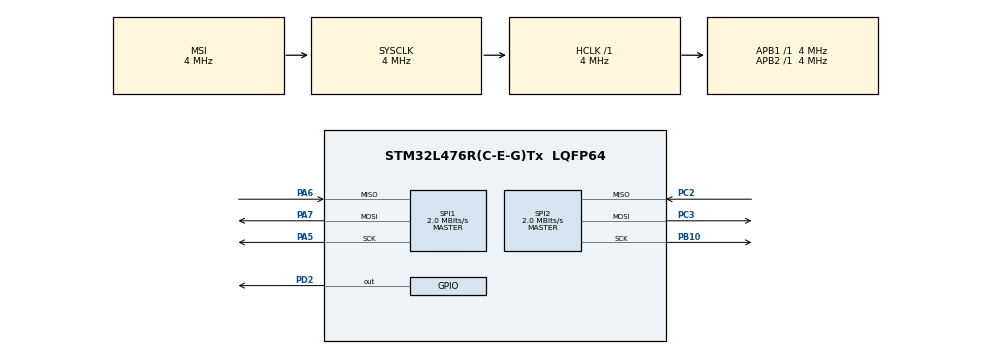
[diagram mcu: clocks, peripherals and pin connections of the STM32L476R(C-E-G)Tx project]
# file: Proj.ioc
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Mcu.Family=STM32L4
Mcu.Name=STM32L476R(C-E-G)Tx
Mcu.Package=LQFP64
NVIC.PriorityGroup=NVIC_PRIORITYGROUP_4
PA5.Mode=Full_Duplex_Master
PA5.Signal=SPI1_SCK
PA6.Mode=Full_Duplex_Master
PA6.Signal=SPI1_MISO
PA7.Mode=Full_Duplex_Master
PA7.Signal=SPI1_MOSI
PB10.Mode=Full_Duplex_Master
PB10.Signal=SPI2_SCK
PC2.Mode=Full_Duplex_Master
PC2.Signal=SPI2_MISO
PC3.Mode=Full_Duplex_Master
PC3.Signal=SPI2_MOSI
PD2.Signal=GPIO_Output
ProjectManager.HeapSize=0x200
ProjectManager.StackSize=0x400
ProjectManager.TargetToolchain=TrueSTUDIO
RCC.ADCFreq_Value=16000000
RCC.AHBFreq_Value=4000000
RCC.APB1Freq_Value=4000000
RCC.APB1TimFreq_Value=4000000
RCC.APB2Freq_Value=4000000
RCC.APB2TimFreq_Value=4000000
RCC.CortexFreq_Value=4000000
RCC.HCLKFreq_Value=4000000
RCC.HSE_VALUE=8000000
RCC.HSI_VALUE=16000000
RCC.LSE_VALUE=32768
RCC.MSI_VALUE=4000000
RCC.PLLN=10
RCC.SYSCLKFreq_VALUE=4000000
RCC.USBFreq_Value=16000000
RCC.VCOOutputFreq_Value=40000000
SPI1.CalculateBaudRate=2.0 MBits/s
SPI1.Direction=SPI_DIRECTION_2LINES
SPI1.Mode=SPI_MODE_MASTER
SPI1.VirtualType=VM_MASTER
SPI2.CalculateBaudRate=2.0 MBits/s
SPI2.Direction=SPI_DIRECTION_2LINES
SPI2.Mode=SPI_MODE_MASTER
SPI2.VirtualType=VM_MASTER
board=custom

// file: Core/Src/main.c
/* USER CODE BEGIN Header */
/**
  ******************************************************************************
  * @file           : main.c
  * @brief          : Main program body
  ******************************************************************************
  * @attention
  *
  * <h2><center>&copy; Copyright (c) 2021 STMicroelectronics.
  * All rights reserved.</center></h2>
  *
  * This software component is licensed by ST under BSD 3-Clause license,
  * the "License"; You may not use this file except in compliance with the
  * License. You may obtain a copy of the License at:
  *                        opensource.org/licenses/BSD-3-Clause
  *
  ******************************************************************************
  */
/* USER CODE END Header */
#include "main.h"

SPI_HandleTypeDef hspi1;
SPI_HandleTypeDef hspi2;

/* USER CODE BEGIN PV */
//некоторые дефайны для управления ножкой Chip Select
#define cs_set() HAL_GPIO_WritePin(GPIOD, GPIO_PIN_2, GPIO_PIN_RESET)
#define cs_reset() HAL_GPIO_WritePin(GPIOD, GPIO_PIN_2, GPIO_PIN_SET)
#define cs_strob() cs_reset();cs_set()
uint8_t aTxBuffer[]={0xFF, 0xFF, 0xFF, 0xFF};

/* USER CODE END PV */

void SystemClock_Config(void);
static void MX_GPIO_Init(void);
static void MX_SPI1_Init(void);
static void MX_SPI2_Init(void);

int main(void)
{
  /* USER CODE BEGIN 1 */
	uint8_t i=0;
  /* USER CODE END 1 */

  /* MCU Configuration--------------------------------------------------------*/

  /* Reset of all peripherals, Initializes the Flash interface and the Systick. */
  HAL_Init();

  /* Configure the system clock */
  SystemClock_Config();

  /* Initialize all configured peripherals */
  MX_GPIO_Init();
  MX_SPI1_Init();
  MX_SPI2_Init();

  /* Infinite loop */
  /* USER CODE BEGIN WHILE */
  while (1)
  {
	  asm("nop");//
		for(i=0;i<=255;i++)
		{
			aTxBuffer[0]=i;
//			aTxBuffer[0]=0xAA;
			HAL_SPI_Transmit (&hspi1, (uint8_t*)aTxBuffer, 1, 0xFFFFFFFF);
			cs_strob();
			HAL_Delay(300);
		}

    /* USER CODE END WHILE */

  }
}

void SystemClock_Config(void)
{
  RCC_OscInitTypeDef RCC_OscInitStruct = {0};
  RCC_ClkInitTypeDef RCC_ClkInitStruct = {0};

  /** Initializes the RCC Oscillators according to the specified parameters
  * in the RCC_OscInitTypeDef structure.
  */
  RCC_OscInitStruct.OscillatorType = RCC_OSCILLATORTYPE_MSI;
  RCC_OscInitStruct.MSIState = RCC_MSI_ON;
  RCC_OscInitStruct.MSICalibrationValue = 0;
  RCC_OscInitStruct.MSIClockRange = RCC_MSIRANGE_6;
  RCC_OscInitStruct.PLL.PLLState = RCC_PLL_NONE;
  if (HAL_RCC_OscConfig(&RCC_OscInitStruct) != HAL_OK)
  {
    Error_Handler();
  }
  /** Initializes the CPU, AHB and APB buses clocks
  */
  RCC_ClkInitStruct.ClockType = RCC_CLOCKTYPE_HCLK|RCC_CLOCKTYPE_SYSCLK
                              |RCC_CLOCKTYPE_PCLK1|RCC_CLOCKTYPE_PCLK2;
  RCC_ClkInitStruct.SYSCLKSource = RCC_SYSCLKSOURCE_MSI;
  RCC_ClkInitStruct.AHBCLKDivider = RCC_SYSCLK_DIV1;
  RCC_ClkInitStruct.APB1CLKDivider = RCC_HCLK_DIV1;
  RCC_ClkInitStruct.APB2CLKDivider = RCC_HCLK_DIV1;

  if (HAL_RCC_ClockConfig(&RCC_ClkInitStruct, FLASH_LATENCY_0) != HAL_OK)
  {
    Error_Handler();
  }
  /** Configure the main internal regulator output voltage
  */
  if (HAL_PWREx_ControlVoltageScaling(PWR_REGULATOR_VOLTAGE_SCALE1) != HAL_OK)
  {
    Error_Handler();
  }
}

static void MX_SPI1_Init(void)
{

  /* SPI1 parameter configuration*/
  hspi1.Instance = SPI1;
  hspi1.Init.Mode = SPI_MODE_MASTER;
  hspi1.Init.Direction = SPI_DIRECTION_2LINES;
  hspi1.Init.DataSize = SPI_DATASIZE_4BIT;
  hspi1.Init.CLKPolarity = SPI_POLARITY_LOW;
  hspi1.Init.CLKPhase = SPI_PHASE_1EDGE;
  hspi1.Init.NSS = SPI_NSS_SOFT;
  hspi1.Init.BaudRatePrescaler = SPI_BAUDRATEPRESCALER_2;
  hspi1.Init.FirstBit = SPI_FIRSTBIT_MSB;
  hspi1.Init.TIMode = SPI_TIMODE_DISABLE;
  hspi1.Init.CRCCalculation = SPI_CRCCALCULATION_DISABLE;
  hspi1.Init.CRCPolynomial = 7;
  hspi1.Init.CRCLength = SPI_CRC_LENGTH_DATASIZE;
  hspi1.Init.NSSPMode = SPI_NSS_PULSE_ENABLE;
  if (HAL_SPI_Init(&hspi1) != HAL_OK)
  {
    Error_Handler();
  }

}

static void MX_SPI2_Init(void)
{

  /* SPI2 parameter configuration*/
  hspi2.Instance = SPI2;
  hspi2.Init.Mode = SPI_MODE_MASTER;
  hspi2.Init.Direction = SPI_DIRECTION_2LINES;
  hspi2.Init.DataSize = SPI_DATASIZE_4BIT;
  hspi2.Init.CLKPolarity = SPI_POLARITY_LOW;
  hspi2.Init.CLKPhase = SPI_PHASE_1EDGE;
  hspi2.Init.NSS = SPI_NSS_SOFT;
  hspi2.Init.BaudRatePrescaler = SPI_BAUDRATEPRESCALER_2;
  hspi2.Init.FirstBit = SPI_FIRSTBIT_MSB;
  hspi2.Init.TIMode = SPI_TIMODE_DISABLE;
  hspi2.Init.CRCCalculation = SPI_CRCCALCULATION_DISABLE;
  hspi2.Init.CRCPolynomial = 7;
  hspi2.Init.CRCLength = SPI_CRC_LENGTH_DATASIZE;
  hspi2.Init.NSSPMode = SPI_NSS_PULSE_ENABLE;
  if (HAL_SPI_Init(&hspi2) != HAL_OK)
  {
    Error_Handler();
  }

}

static void MX_GPIO_Init(void)
{
  GPIO_InitTypeDef GPIO_InitStruct = {0};

  /* GPIO Ports Clock Enable */
  __HAL_RCC_GPIOC_CLK_ENABLE();
  __HAL_RCC_GPIOA_CLK_ENABLE();
  __HAL_RCC_GPIOB_CLK_ENABLE();
  __HAL_RCC_GPIOD_CLK_ENABLE();

  /*Configure GPIO pin Output Level */
  HAL_GPIO_WritePin(GPIOD, GPIO_PIN_2, GPIO_PIN_RESET);

  /*Configure GPIO pin : PD2 */
  GPIO_InitStruct.Pin = GPIO_PIN_2;
  GPIO_InitStruct.Mode = GPIO_MODE_OUTPUT_PP;
  GPIO_InitStruct.Pull = GPIO_NOPULL;
  GPIO_InitStruct.Speed = GPIO_SPEED_FREQ_LOW;
  HAL_GPIO_Init(GPIOD, &GPIO_InitStruct);

}

void Error_Handler(void)
{
  __disable_irq();
  while (1)
  {
  }
}

/************************ (C) COPYRIGHT STMicroelectronics *****END OF FILE****/
